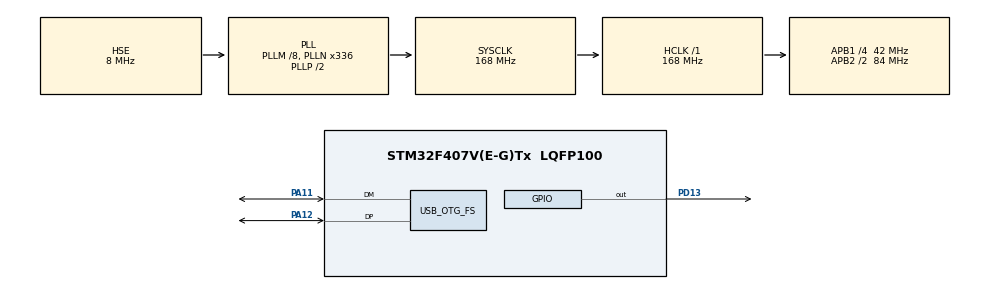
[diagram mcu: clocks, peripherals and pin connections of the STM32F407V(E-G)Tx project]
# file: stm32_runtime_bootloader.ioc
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Mcu.Family=STM32F4
Mcu.Name=STM32F407V(E-G)Tx
Mcu.Package=LQFP100
NVIC.OTG_FS_IRQn=true\:0\:0\:false\:false\:true\:true\:true\:true
NVIC.PriorityGroup=NVIC_PRIORITYGROUP_0
PA11.Mode=Device_Only
PA11.Signal=USB_OTG_FS_DM
PA12.Mode=Device_Only
PA12.Signal=USB_OTG_FS_DP
PA13.Mode=Serial_Wire
PA13.Signal=SYS_JTMS-SWDIO
PA14.Mode=Serial_Wire
PA14.Signal=SYS_JTCK-SWCLK
PC14-OSC32_IN.Mode=LSE-External-Oscillator
PC14-OSC32_IN.Signal=RCC_OSC32_IN
PC15-OSC32_OUT.Mode=LSE-External-Oscillator
PC15-OSC32_OUT.Signal=RCC_OSC32_OUT
PD13.Signal=GPIO_Output
PH0-OSC_IN.Mode=HSE-External-Oscillator
PH0-OSC_IN.Signal=RCC_OSC_IN
PH1-OSC_OUT.Mode=HSE-External-Oscillator
PH1-OSC_OUT.Signal=RCC_OSC_OUT
ProjectManager.HeapSize=0x200
ProjectManager.StackSize=0x400
ProjectManager.TargetToolchain=STM32CubeIDE
RCC.48MHZClocksFreq_Value=48000000
RCC.AHBFreq_Value=168000000
RCC.APB1CLKDivider=RCC_HCLK_DIV4
RCC.APB1Freq_Value=42000000
RCC.APB1TimFreq_Value=84000000
RCC.APB2CLKDivider=RCC_HCLK_DIV2
RCC.APB2Freq_Value=84000000
RCC.APB2TimFreq_Value=168000000
RCC.CortexFreq_Value=168000000
RCC.HCLKFreq_Value=168000000
RCC.HSE_VALUE=8000000
RCC.HSI_VALUE=16000000
RCC.PLLM=8
RCC.PLLN=336
RCC.PLLQ=7
RCC.SYSCLKFreq_VALUE=168000000
RCC.SYSCLKSource=RCC_SYSCLKSOURCE_PLLCLK
RCC.VCOOutputFreq_Value=336000000
USB_DEVICE.CLASS_NAME_FS=CDC
USB_DEVICE.PRODUCT_STRING_CDC_FS=STM32 Virtual Port
USB_DEVICE.VirtualMode-CDC_FS=Cdc
USB_DEVICE.VirtualModeFS=Cdc_FS
USB_OTG_FS.VirtualMode=Device_Only
VP_USB_DEVICE_VS_USB_DEVICE_CDC_FS.Mode=CDC_FS
board=STM32F407G-DISC1

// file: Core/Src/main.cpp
/* USER CODE BEGIN Header */
/*
 * Adi: Harun
 * Soyadi: Gül
 * Tarih: 13.07.2024
 *
 */
/* USER CODE END Header */
#include "main.h"
#include "usb_device.h"

/* USER CODE BEGIN Includes */
#include "parser.h"
#include "string.h"
#include "stdbool.h"
#include "usbd_cdc_if.h"
/* USER CODE END Includes */

/* USER CODE BEGIN PV */

uint16_t hatalimesajsayisi,hatasizmesajsayisi;
char txbuffer[80]={};
volatile uint8_t rxbufferindexi;
volatile bool usbbayragi=false;

char usb_receive_buffer[2048][50];
usbgelendata usbayiklanmisdata;

uint32_t extended_linear_address;
uint32_t start_linear_address=0;
uint32_t resultaddress;

char son[3]="\r\n";

/* USER CODE END PV */

void SystemClock_Config(void);
static void MX_GPIO_Init(void);

/* USER CODE BEGIN 0 */
void Flash_Erase_Sector0(void) { // SECTOR SIFIRI TEMIZLEYEN FONKSIYON
    HAL_StatusTypeDef status;
    FLASH_EraseInitTypeDef eraseInitStruct;
    uint32_t sectorError = 0;

    HAL_FLASH_Unlock();

    eraseInitStruct.TypeErase = FLASH_TYPEERASE_SECTORS;
    eraseInitStruct.Sector = FLASH_SECTOR_0;
    eraseInitStruct.NbSectors = 1;
    eraseInitStruct.VoltageRange = FLASH_VOLTAGE_RANGE_2;

    status = HAL_FLASHEx_Erase(&eraseInitStruct, &sectorError);

    if (status != HAL_OK) {
        // Handle error
    	Error_Handler();
    }

    HAL_FLASH_Lock();
}

void Flash_Erase_Sector1(void) { // SEKTOR1 TEMIZLEYEN FONKSIYON
    HAL_StatusTypeDef status;
    FLASH_EraseInitTypeDef eraseInitStruct;
    uint32_t sectorError = 0;

    HAL_FLASH_Unlock();

    eraseInitStruct.TypeErase = FLASH_TYPEERASE_SECTORS;
    eraseInitStruct.Sector = FLASH_SECTOR_1;
    eraseInitStruct.NbSectors = 1;
    eraseInitStruct.VoltageRange = FLASH_VOLTAGE_RANGE_2;

    status = HAL_FLASHEx_Erase(&eraseInitStruct, &sectorError);

    if (status != HAL_OK) {
        // Handle error
    	Error_Handler();
    }

    HAL_FLASH_Lock();
}
/* USER CODE END 0 */

int main(void)
{

  /* MCU Configuration--------------------------------------------------------*/

  /* Reset of all peripherals, Initializes the Flash interface and the Systick. */
  HAL_Init();

  /* Configure the system clock */
  SystemClock_Config();

  /* Initialize all configured peripherals */
  MX_GPIO_Init();
  MX_USB_DEVICE_Init();
  /* USER CODE BEGIN 2 */

  Flash_Erase_Sector0(); // SEKTOR1 VE SEKTOR2NIN TEMIZLENMESI
  Flash_Erase_Sector1();

  //KART UZERINDEKI TURUNCU LEDI YAKIYORUM. YENI FIRMWAREYE GECTIGIMDE BU KODUN CALISMADIGINI GORMEK ISTEDIM
  HAL_GPIO_WritePin(GPIOD, GPIO_PIN_13, GPIO_PIN_SET);

  /* USER CODE END 2 */

  /* Infinite loop */
  while (1)
  {

    /* USER CODE BEGIN 3 */
	  //HAL_Delay(1000);
	  if(usbbayragi) { // CDC_Receive_FS FONKSIYONUNDA VERI ALIMI TAMAMLANDIGINDA BU BAYRAK KALDIRILIR
		  usbbayragi=false;
		  for(uint16_t satir=0;satir<satirsayisi;++satir) { // USBDEN ALINAN TUM DATA ISLENMEK UZERE GONDERILIR
			  if(strlen(usb_receive_buffer[satir])>0) {
				 datayiayiklavekullan(usb_receive_buffer[satir],satir);
//				 CDC_Transmit_FS((uint8_t*)usb_receive_buffer[satir], strlen(usb_receive_buffer[satir]));
//				  HAL_Delay(3);
//				  CDC_Transmit_FS((uint8_t*)son,sizeof(son)/sizeof(son[0]));
			  }
		  }
		  satirsayisi=0;
		  indexsayisi=0;
	  }
  }
  /* USER CODE END 3 */
}

void SystemClock_Config(void)
{
  RCC_OscInitTypeDef RCC_OscInitStruct = {0};
  RCC_ClkInitTypeDef RCC_ClkInitStruct = {0};

  /** Configure the main internal regulator output voltage
  */
  __HAL_RCC_PWR_CLK_ENABLE();
  __HAL_PWR_VOLTAGESCALING_CONFIG(PWR_REGULATOR_VOLTAGE_SCALE1);

  /** Initializes the RCC Oscillators according to the specified parameters
  * in the RCC_OscInitTypeDef structure.
  */
  RCC_OscInitStruct.OscillatorType = RCC_OSCILLATORTYPE_HSE;
  RCC_OscInitStruct.HSEState = RCC_HSE_ON;
  RCC_OscInitStruct.PLL.PLLState = RCC_PLL_ON;
  RCC_OscInitStruct.PLL.PLLSource = RCC_PLLSOURCE_HSE;
  RCC_OscInitStruct.PLL.PLLM = 8;
  RCC_OscInitStruct.PLL.PLLN = 336;
  RCC_OscInitStruct.PLL.PLLP = RCC_PLLP_DIV2;
  RCC_OscInitStruct.PLL.PLLQ = 7;
  if (HAL_RCC_OscConfig(&RCC_OscInitStruct) != HAL_OK)
  {
    Error_Handler();
  }

  /** Initializes the CPU, AHB and APB buses clocks
  */
  RCC_ClkInitStruct.ClockType = RCC_CLOCKTYPE_HCLK|RCC_CLOCKTYPE_SYSCLK
                              |RCC_CLOCKTYPE_PCLK1|RCC_CLOCKTYPE_PCLK2;
  RCC_ClkInitStruct.SYSCLKSource = RCC_SYSCLKSOURCE_PLLCLK;
  RCC_ClkInitStruct.AHBCLKDivider = RCC_SYSCLK_DIV1;
  RCC_ClkInitStruct.APB1CLKDivider = RCC_HCLK_DIV4;
  RCC_ClkInitStruct.APB2CLKDivider = RCC_HCLK_DIV2;

  if (HAL_RCC_ClockConfig(&RCC_ClkInitStruct, FLASH_LATENCY_5) != HAL_OK)
  {
    Error_Handler();
  }
}

static void MX_GPIO_Init(void)
{
  GPIO_InitTypeDef GPIO_InitStruct = {0};

  /* GPIO Ports Clock Enable */
  __HAL_RCC_GPIOC_CLK_ENABLE();
  __HAL_RCC_GPIOH_CLK_ENABLE();
  __HAL_RCC_GPIOD_CLK_ENABLE();
  __HAL_RCC_GPIOA_CLK_ENABLE();

  /*Configure GPIO pin Output Level */
  HAL_GPIO_WritePin(GPIOD, GPIO_PIN_13, GPIO_PIN_RESET);

  /*Configure GPIO pin : PD13 */
  GPIO_InitStruct.Pin = GPIO_PIN_13;
  GPIO_InitStruct.Mode = GPIO_MODE_OUTPUT_PP;
  GPIO_InitStruct.Pull = GPIO_NOPULL;
  GPIO_InitStruct.Speed = GPIO_SPEED_FREQ_LOW;
  HAL_GPIO_Init(GPIOD, &GPIO_InitStruct);

}

void Error_Handler(void)
{
  __disable_irq();
  while (1)
  {
  }
}
